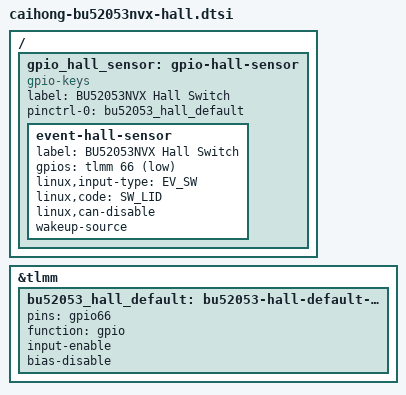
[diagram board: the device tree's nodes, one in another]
// SPDX-License-Identifier: GPL-2.0-only
/*
 * OnePlus Pad Pro (caihong / OPD2404) Hall switch bring-up fragment.
 *
 * Qualcomm SSC registry evidence for BU52053NVX:
 *   - SoC TLMM interrupt pin 66
 *   - no pull
 *   - dual-edge interrupt
 *   - one sensor_vddio rail
 *
 * The SSC registry only names that rail as /pmic/client/sensor_vddio and does
 * not expose the corresponding AP Linux regulator phandle.  Runtime testing
 * confirms that firmware leaves the GPIO-only Hall switch operational.
 */

#include <dt-bindings/gpio/gpio.h>
#include <dt-bindings/input/input.h>

/ {
	gpio_hall_sensor: gpio-hall-sensor {
		compatible = "gpio-keys";
		label = "BU52053NVX Hall Switch";

		pinctrl-names = "default";
		pinctrl-0 = <&bu52053_hall_default>;

		event-hall-sensor {
			label = "BU52053NVX Hall Switch";
			gpios = <&tlmm 66 GPIO_ACTIVE_LOW>;
			linux,input-type = <EV_SW>;
			linux,code = <SW_LID>;
			linux,can-disable;
			wakeup-source;
		};
	};
};

&tlmm {
	bu52053_hall_default: bu52053-hall-default-state {
		pins = "gpio66";
		function = "gpio";
		input-enable;
		bias-disable;
	};
};
